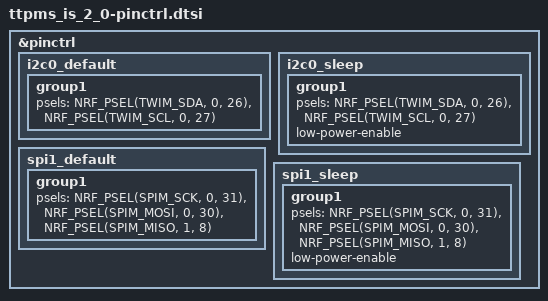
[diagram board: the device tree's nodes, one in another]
&pinctrl {

	i2c0_default: i2c0_default {
		group1 {
			psels = <NRF_PSEL(TWIM_SDA, 0, 26)>,
				<NRF_PSEL(TWIM_SCL, 0, 27)>;
		};
	};

	i2c0_sleep: i2c0_sleep {
		group1 {
			psels = <NRF_PSEL(TWIM_SDA, 0, 26)>,
				<NRF_PSEL(TWIM_SCL, 0, 27)>;
			low-power-enable;
		};
	};

	spi1_default: spi1_default {
		group1 {
			psels = <NRF_PSEL(SPIM_SCK, 0, 31)>,
				<NRF_PSEL(SPIM_MOSI, 0, 30)>,
				<NRF_PSEL(SPIM_MISO, 1, 8)>;
		};
	};

	spi1_sleep: spi1_sleep {
		group1 {
			psels = <NRF_PSEL(SPIM_SCK, 0, 31)>,
				<NRF_PSEL(SPIM_MOSI, 0, 30)>,
				<NRF_PSEL(SPIM_MISO, 1, 8)>;
			low-power-enable;
		};
	};

};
